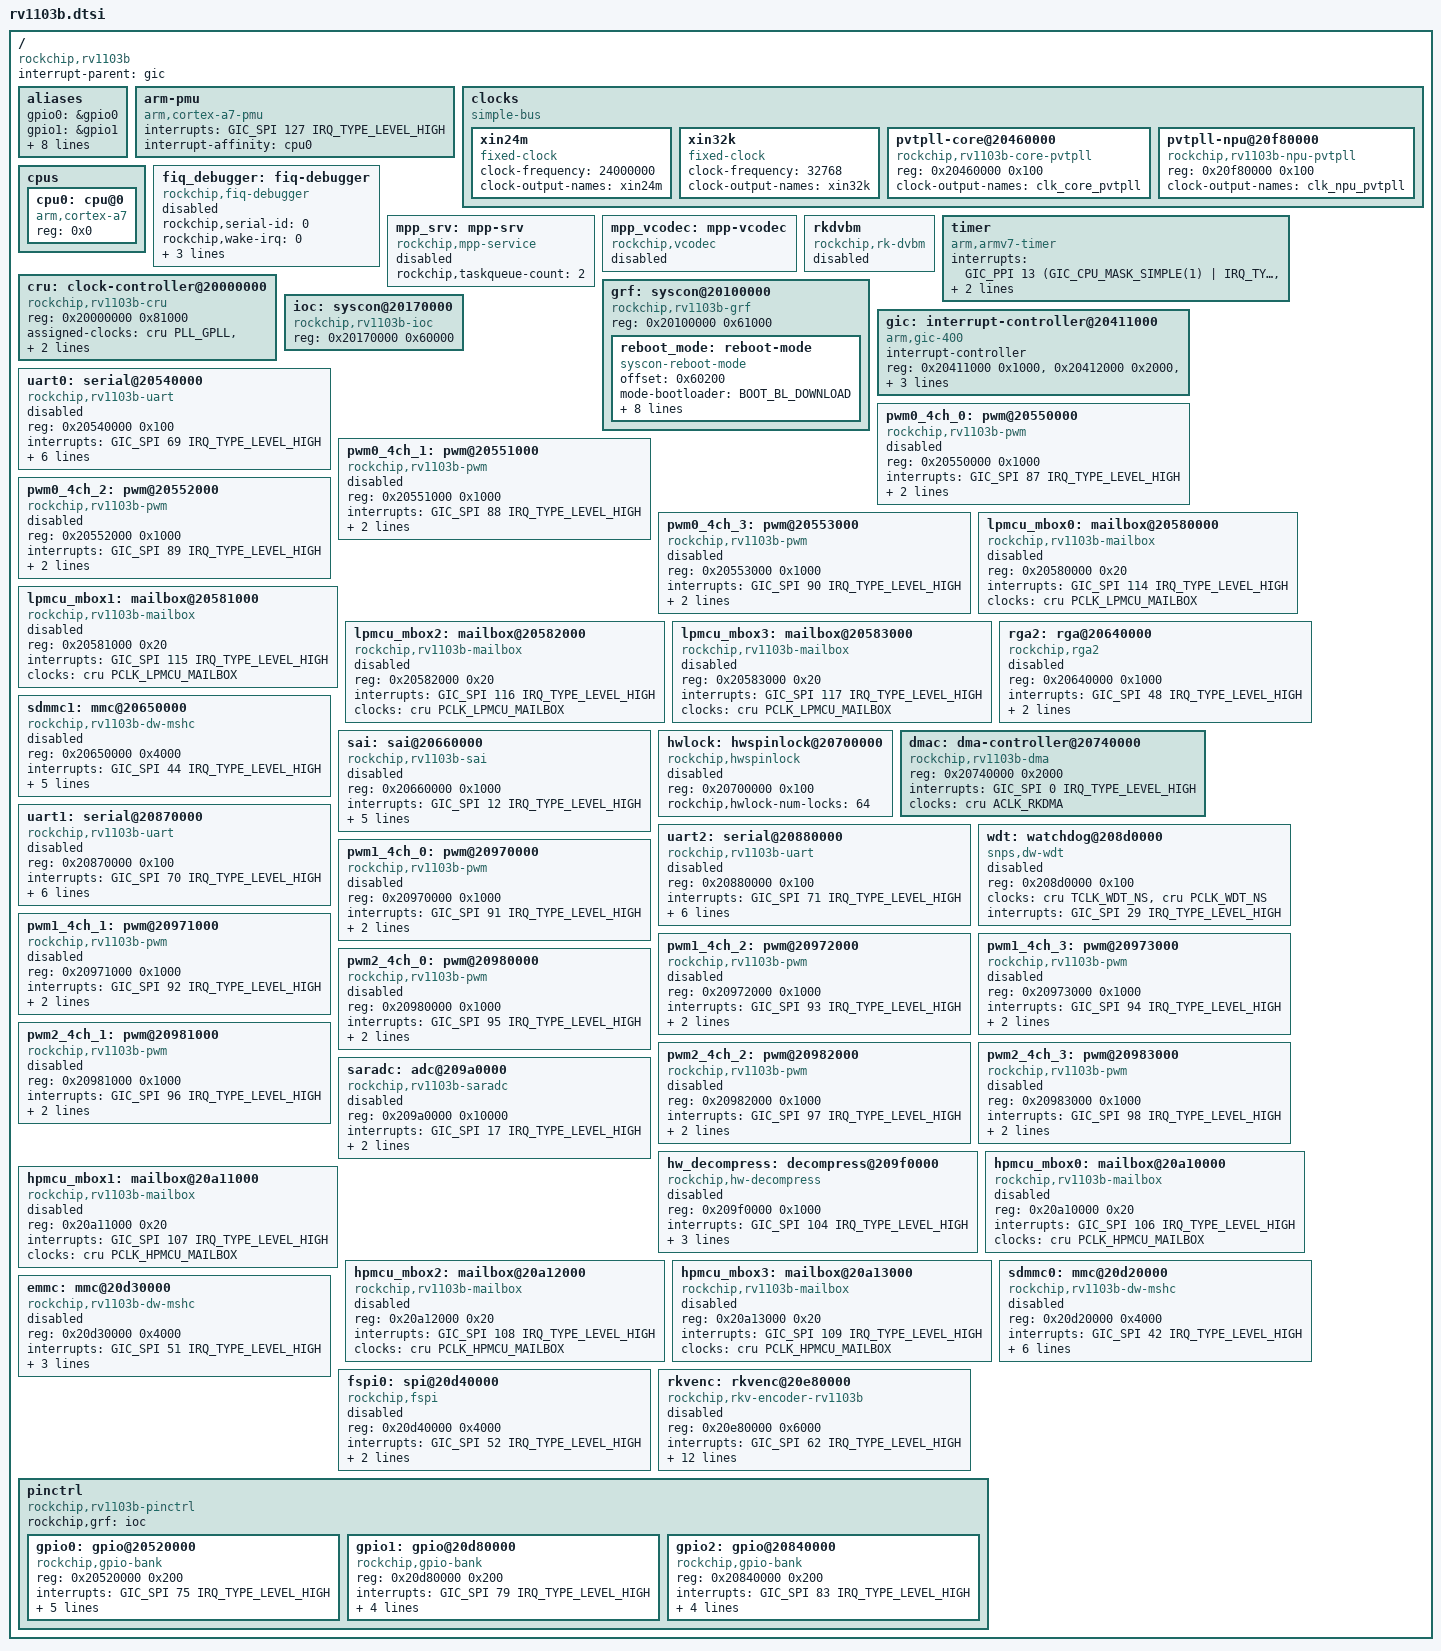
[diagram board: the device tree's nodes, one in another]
// SPDX-License-Identifier: (GPL-2.0+ OR MIT)
/*
 * Copyright (c) 2024 Rockchip Electronics Co., Ltd.
 */

#include <dt-bindings/clock/rockchip,rv1103b-cru.h>
#include <dt-bindings/gpio/gpio.h>
#include <dt-bindings/interrupt-controller/irq.h>
#include <dt-bindings/interrupt-controller/arm-gic.h>
#include <dt-bindings/pinctrl/rockchip.h>
#include <dt-bindings/soc/rockchip,boot-mode.h>
#include <dt-bindings/soc/rockchip-system-status.h>
#include <dt-bindings/thermal/thermal.h>

/ {
	#address-cells = <1>;
	#size-cells = <1>;

	compatible = "rockchip,rv1103b";

	interrupt-parent = <&gic>;

	aliases {
		gpio0 = &gpio0;
		gpio1 = &gpio1;
		gpio2 = &gpio2;
		mmc0 = &emmc;
		mmc1 = &sdmmc0;
		mmc2 = &sdmmc1;
		serial0 = &uart0;
		serial1 = &uart1;
		serial2 = &uart2;
		spi1 = &fspi0;
	};

	arm-pmu {
		compatible = "arm,cortex-a7-pmu";
		interrupts = <GIC_SPI 127 IRQ_TYPE_LEVEL_HIGH>;
		interrupt-affinity = <&cpu0>;
	};

	clocks {
		compatible = "simple-bus";
		#address-cells = <1>;
		#size-cells = <1>;
		ranges;

		xin24m: xin24m {
			compatible = "fixed-clock";
			#clock-cells = <0>;
			clock-frequency = <24000000>;
			clock-output-names = "xin24m";
		};

		xin32k: xin32k {
			compatible = "fixed-clock";
			#clock-cells = <0>;
			clock-frequency = <32768>;
			clock-output-names = "xin32k";
		};

		pvtpll-core@20460000 {
			compatible = "rockchip,rv1103b-core-pvtpll";
			reg = <0x20460000 0x100>;
			clock-output-names = "clk_core_pvtpll";
		};

		pvtpll-npu@20f80000 {
			compatible = "rockchip,rv1103b-npu-pvtpll";
			reg = <0x20f80000 0x100>;
			clock-output-names = "clk_npu_pvtpll";
		};
	};

	cpus {
		#address-cells = <1>;
		#size-cells = <0>;

		cpu0: cpu@0 {
			device_type = "cpu";
			compatible = "arm,cortex-a7";
			reg = <0x0>;
		};
	};

	fiq_debugger: fiq-debugger {
		compatible = "rockchip,fiq-debugger";
		rockchip,serial-id = <0>;
		rockchip,wake-irq = <0>;
		rockchip,irq-mode-enable = <0>;
		rockchip,baudrate = <115200>;  /* Only 115200 and 1500000 */
		interrupts = <GIC_SPI 125 IRQ_TYPE_LEVEL_HIGH>;
		status = "disabled";
	};

	mpp_srv: mpp-srv {
		compatible = "rockchip,mpp-service";
		rockchip,taskqueue-count = <2>;
		status = "disabled";
	};

	mpp_vcodec: mpp-vcodec {
		compatible = "rockchip,vcodec";
		status = "disabled";
	};

	rkdvbm: rkdvbm {
		compatible = "rockchip,rk-dvbm";
		status = "disabled";
	};

	timer {
		compatible = "arm,armv7-timer";
		interrupts = <GIC_PPI 13 (GIC_CPU_MASK_SIMPLE(1) | IRQ_TYPE_LEVEL_HIGH)>,
			     <GIC_PPI 14 (GIC_CPU_MASK_SIMPLE(1) | IRQ_TYPE_LEVEL_HIGH)>;
		clock-frequency = <24000000>;
	};

	cru: clock-controller@20000000 {
		compatible = "rockchip,rv1103b-cru";
		reg = <0x20000000 0x81000>;
		#clock-cells = <1>;
		#reset-cells = <1>;

		assigned-clocks =
			<&cru PLL_GPLL>, <&cru CLK_GPLL_DIV12>;
		assigned-clock-rates =
			<1188000000>, <100000000>;
	};

	/*
	 * Merge all GRF, each independent GRF offset is shown as bellow:
	 * VEPU_GRF:		0x20100000
	 * NPU_GRF:		0x20110000
	 * VI_GRF:		0x20120000
	 * CPU_GRF:		0x20130000
	 * DDR_GRF:		0x20140000
	 * SYS_GRF:		0x20150000
	 * PMU_GRF:		0x20160000
	 */
	grf: syscon@20100000 {
		compatible = "rockchip,rv1103b-grf", "syscon", "simple-mfd";
		reg = <0x20100000 0x61000>;

		reboot_mode: reboot-mode {
			compatible = "syscon-reboot-mode";
			offset = <0x60200>;
			mode-bootloader = <BOOT_BL_DOWNLOAD>;
			mode-charge = <BOOT_CHARGING>;
			mode-fastboot = <BOOT_FASTBOOT>;
			mode-loader = <BOOT_BL_DOWNLOAD>;
			mode-normal = <BOOT_NORMAL>;
			mode-recovery = <BOOT_RECOVERY>;
			mode-ums = <BOOT_UMS>;
			mode-panic = <BOOT_PANIC>;
			mode-watchdog = <BOOT_WATCHDOG>;
		};
	};

	ioc: syscon@20170000 {
		compatible = "rockchip,rv1103b-ioc", "syscon";
		reg = <0x20170000 0x60000>;
	};

	gic: interrupt-controller@20411000 {
		compatible = "arm,gic-400";
		interrupt-controller;
		#interrupt-cells = <3>;
		#address-cells = <0>;

		reg = <0x20411000 0x1000>,
		      <0x20412000 0x2000>,
		      <0x20414000 0x2000>,
		      <0x20416000 0x2000>;
		interrupts = <GIC_PPI 9 (GIC_CPU_MASK_SIMPLE(1) | IRQ_TYPE_LEVEL_HIGH)>;
	};

	uart0: serial@20540000 {
		compatible = "rockchip,rv1103b-uart", "snps,dw-apb-uart";
		reg = <0x20540000 0x100>;
		interrupts = <GIC_SPI 69 IRQ_TYPE_LEVEL_HIGH>;
		reg-shift = <2>;
		reg-io-width = <4>;
		dmas = <&dmac 1>, <&dmac 0>;
		clock-frequency = <24000000>;
		clocks = <&cru SCLK_UART0>, <&cru PCLK_UART0>;
		clock-names = "baudclk", "apb_pclk";
		pinctrl-names = "default";
		pinctrl-0 = <&uart0m0_xfer_pins>;
		status = "disabled";
	};

	pwm0_4ch_0: pwm@20550000 {
		compatible = "rockchip,rv1103b-pwm", "rockchip,rk3576-pwm";
		reg = <0x20550000 0x1000>;
		interrupts = <GIC_SPI 87 IRQ_TYPE_LEVEL_HIGH>;
		#pwm-cells = <3>;
		pinctrl-names = "active";
		pinctrl-0 = <&pwm0m0_ch0_pins>;
		clocks = <&cru CLK_PWM0>, <&cru PCLK_PWM0>;
		clock-names = "pwm", "pclk";
		status = "disabled";
	};

	pwm0_4ch_1: pwm@20551000 {
		compatible = "rockchip,rv1103b-pwm", "rockchip,rk3576-pwm";
		reg = <0x20551000 0x1000>;
		interrupts = <GIC_SPI 88 IRQ_TYPE_LEVEL_HIGH>;
		#pwm-cells = <3>;
		pinctrl-names = "active";
		pinctrl-0 = <&pwm0m0_ch1_pins>;
		clocks = <&cru CLK_PWM0>, <&cru PCLK_PWM0>;
		clock-names = "pwm", "pclk";
		status = "disabled";
	};

	pwm0_4ch_2: pwm@20552000 {
		compatible = "rockchip,rv1103b-pwm", "rockchip,rk3576-pwm";
		reg = <0x20552000 0x1000>;
		interrupts = <GIC_SPI 89 IRQ_TYPE_LEVEL_HIGH>;
		#pwm-cells = <3>;
		pinctrl-names = "active";
		pinctrl-0 = <&pwm0m0_ch2_pins>;
		clocks = <&cru CLK_PWM0>, <&cru PCLK_PWM0>;
		clock-names = "pwm", "pclk";
		status = "disabled";
	};

	pwm0_4ch_3: pwm@20553000 {
		compatible = "rockchip,rv1103b-pwm", "rockchip,rk3576-pwm";
		reg = <0x20553000 0x1000>;
		interrupts = <GIC_SPI 90 IRQ_TYPE_LEVEL_HIGH>;
		#pwm-cells = <3>;
		pinctrl-names = "active";
		pinctrl-0 = <&pwm0m0_ch3_pins>;
		clocks = <&cru CLK_PWM0>, <&cru PCLK_PWM0>;
		clock-names = "pwm", "pclk";
		status = "disabled";
	};

	lpmcu_mbox0: mailbox@20580000 {
		compatible = "rockchip,rv1103b-mailbox", "rockchip,rk3576-mailbox";
		reg = <0x20580000 0x20>;
		interrupts = <GIC_SPI 114 IRQ_TYPE_LEVEL_HIGH>;
		clocks = <&cru PCLK_LPMCU_MAILBOX>;
		clock-names = "pclk_mailbox";
		#mbox-cells = <1>;
		status = "disabled";
	};

	lpmcu_mbox1: mailbox@20581000 {
		compatible = "rockchip,rv1103b-mailbox", "rockchip,rk3576-mailbox";
		reg = <0x20581000 0x20>;
		interrupts = <GIC_SPI 115 IRQ_TYPE_LEVEL_HIGH>;
		clocks = <&cru PCLK_LPMCU_MAILBOX>;
		clock-names = "pclk_mailbox";
		#mbox-cells = <1>;
		status = "disabled";
	};

	lpmcu_mbox2: mailbox@20582000 {
		compatible = "rockchip,rv1103b-mailbox", "rockchip,rk3576-mailbox";
		reg = <0x20582000 0x20>;
		interrupts = <GIC_SPI 116 IRQ_TYPE_LEVEL_HIGH>;
		clocks = <&cru PCLK_LPMCU_MAILBOX>;
		clock-names = "pclk_mailbox";
		#mbox-cells = <1>;
		status = "disabled";
	};

	lpmcu_mbox3: mailbox@20583000 {
		compatible = "rockchip,rv1103b-mailbox", "rockchip,rk3576-mailbox";
		reg = <0x20583000 0x20>;
		interrupts = <GIC_SPI 117 IRQ_TYPE_LEVEL_HIGH>;
		clocks = <&cru PCLK_LPMCU_MAILBOX>;
		clock-names = "pclk_mailbox";
		#mbox-cells = <1>;
		status = "disabled";
	};

	rga2: rga@20640000 {
		compatible = "rockchip,rga2";
		reg = <0x20640000 0x1000>;
		interrupts = <GIC_SPI 48 IRQ_TYPE_LEVEL_HIGH>;
		interrupt-names = "rga2_irq";
		clocks = <&cru ACLK_RGA>, <&cru HCLK_RGA>, <&cru CLK_CORE_RGA>;
		clock-names = "aclk_rga", "hclk_rga", "clk_rga";
		status = "disabled";
	};

	sdmmc1: mmc@20650000 {
		compatible = "rockchip,rv1103b-dw-mshc", "rockchip,rk3288-dw-mshc";
		reg = <0x20650000 0x4000>;
		interrupts = <GIC_SPI 44 IRQ_TYPE_LEVEL_HIGH>;
		clocks = <&cru HCLK_SDMMC1>, <&cru CCLK_SDMMC1>;
		clock-names = "biu", "ciu";
		fifo-depth = <0x100>;
		max-frequency = <150000000>;
		pinctrl-names = "default";
		pinctrl-0 = <&sdmmc1_clk_pins &sdmmc1_cmd_pins &sdmmc1_bus4_pins>;
		status = "disabled";
	};

	sai: sai@20660000 {
		compatible = "rockchip,rv1103b-sai", "rockchip,sai-v1";
		reg = <0x20660000 0x1000>;
		interrupts = <GIC_SPI 12 IRQ_TYPE_LEVEL_HIGH>;
		clocks = <&cru MCLK_SAI>, <&cru HCLK_SAI>;
		clock-names = "mclk", "hclk";
		dmas = <&dmac 11>, <&dmac 10>;
		dma-names = "tx", "rx";
		resets = <&cru SRST_MRESETN_SAI>, <&cru SRST_HRESETN_SAI>;
		reset-names = "m", "h";
		#sound-dai-cells = <0>;
		sound-name-prefix = "SAI";
		status = "disabled";
	};

	hwlock: hwspinlock@20700000 {
		compatible = "rockchip,hwspinlock";
		reg = <0x20700000 0x100>;
		#hwlock-cells = <1>;
		rockchip,hwlock-num-locks = <64>;
		status = "disabled";
	};

	dmac: dma-controller@20740000 {
		compatible = "rockchip,rv1103b-dma", "rockchip,dma";
		reg = <0x20740000 0x2000>;
		interrupts = <GIC_SPI 0 IRQ_TYPE_LEVEL_HIGH>;
		clocks = <&cru ACLK_RKDMA>;
		clock-names = "aclk";
		#dma-cells = <1>;
	};

	uart1: serial@20870000 {
		compatible = "rockchip,rv1103b-uart", "snps,dw-apb-uart";
		reg = <0x20870000 0x100>;
		interrupts = <GIC_SPI 70 IRQ_TYPE_LEVEL_HIGH>;
		reg-shift = <2>;
		reg-io-width = <4>;
		dmas = <&dmac 3>, <&dmac 2>;
		clock-frequency = <24000000>;
		clocks = <&cru SCLK_UART1>, <&cru PCLK_UART1>;
		clock-names = "baudclk", "apb_pclk";
		pinctrl-names = "default";
		pinctrl-0 = <&uart1m0_xfer_pins>;
		status = "disabled";
	};

	uart2: serial@20880000 {
		compatible = "rockchip,rv1103b-uart", "snps,dw-apb-uart";
		reg = <0x20880000 0x100>;
		interrupts = <GIC_SPI 71 IRQ_TYPE_LEVEL_HIGH>;
		reg-shift = <2>;
		reg-io-width = <4>;
		dmas = <&dmac 5>, <&dmac 4>;
		clock-frequency = <24000000>;
		clocks = <&cru SCLK_UART2>, <&cru PCLK_UART2>;
		clock-names = "baudclk", "apb_pclk";
		pinctrl-names = "default";
		pinctrl-0 = <&uart2m0_xfer_pins>;
		status = "disabled";
	};

	wdt: watchdog@208d0000 {
		compatible = "snps,dw-wdt";
		reg = <0x208d0000 0x100>;
		clocks = <&cru TCLK_WDT_NS>, <&cru PCLK_WDT_NS>;
		clock-names = "tclk", "pclk";
		interrupts = <GIC_SPI 29 IRQ_TYPE_LEVEL_HIGH>;
		status = "disabled";
	};

	pwm1_4ch_0: pwm@20970000 {
		compatible = "rockchip,rv1103b-pwm", "rockchip,rk3576-pwm";
		reg = <0x20970000 0x1000>;
		interrupts = <GIC_SPI 91 IRQ_TYPE_LEVEL_HIGH>;
		#pwm-cells = <3>;
		pinctrl-names = "active";
		pinctrl-0 = <&pwm1m0_ch0_pins>;
		clocks = <&cru CLK_PWM1>, <&cru PCLK_PWM1>;
		clock-names = "pwm", "pclk";
		status = "disabled";
	};

	pwm1_4ch_1: pwm@20971000 {
		compatible = "rockchip,rv1103b-pwm", "rockchip,rk3576-pwm";
		reg = <0x20971000 0x1000>;
		interrupts = <GIC_SPI 92 IRQ_TYPE_LEVEL_HIGH>;
		#pwm-cells = <3>;
		pinctrl-names = "active";
		pinctrl-0 = <&pwm1m0_ch1_pins>;
		clocks = <&cru CLK_PWM1>, <&cru PCLK_PWM1>;
		clock-names = "pwm", "pclk";
		status = "disabled";
	};

	pwm1_4ch_2: pwm@20972000 {
		compatible = "rockchip,rv1103b-pwm", "rockchip,rk3576-pwm";
		reg = <0x20972000 0x1000>;
		interrupts = <GIC_SPI 93 IRQ_TYPE_LEVEL_HIGH>;
		#pwm-cells = <3>;
		pinctrl-names = "active";
		pinctrl-0 = <&pwm1m0_ch2_pins>;
		clocks = <&cru CLK_PWM1>, <&cru PCLK_PWM1>;
		clock-names = "pwm", "pclk";
		status = "disabled";
	};

	pwm1_4ch_3: pwm@20973000 {
		compatible = "rockchip,rv1103b-pwm", "rockchip,rk3576-pwm";
		reg = <0x20973000 0x1000>;
		interrupts = <GIC_SPI 94 IRQ_TYPE_LEVEL_HIGH>;
		#pwm-cells = <3>;
		pinctrl-names = "active";
		pinctrl-0 = <&pwm1m0_ch3_pins>;
		clocks = <&cru CLK_PWM1>, <&cru PCLK_PWM1>;
		clock-names = "pwm", "pclk";
		status = "disabled";
	};

	pwm2_4ch_0: pwm@20980000 {
		compatible = "rockchip,rv1103b-pwm", "rockchip,rk3576-pwm";
		reg = <0x20980000 0x1000>;
		interrupts = <GIC_SPI 95 IRQ_TYPE_LEVEL_HIGH>;
		#pwm-cells = <3>;
		pinctrl-names = "active";
		pinctrl-0 = <&pwm2m0_ch0_pins>;
		clocks = <&cru CLK_PWM2>, <&cru PCLK_PWM2>;
		clock-names = "pwm", "pclk";
		status = "disabled";
	};

	pwm2_4ch_1: pwm@20981000 {
		compatible = "rockchip,rv1103b-pwm", "rockchip,rk3576-pwm";
		reg = <0x20981000 0x1000>;
		interrupts = <GIC_SPI 96 IRQ_TYPE_LEVEL_HIGH>;
		#pwm-cells = <3>;
		pinctrl-names = "active";
		pinctrl-0 = <&pwm2m0_ch1_pins>;
		clocks = <&cru CLK_PWM2>, <&cru PCLK_PWM2>;
		clock-names = "pwm", "pclk";
		status = "disabled";
	};

	pwm2_4ch_2: pwm@20982000 {
		compatible = "rockchip,rv1103b-pwm", "rockchip,rk3576-pwm";
		reg = <0x20982000 0x1000>;
		interrupts = <GIC_SPI 97 IRQ_TYPE_LEVEL_HIGH>;
		#pwm-cells = <3>;
		pinctrl-names = "active";
		pinctrl-0 = <&pwm2m0_ch2_pins>;
		clocks = <&cru CLK_PWM2>, <&cru PCLK_PWM2>;
		clock-names = "pwm", "pclk";
		status = "disabled";
	};

	pwm2_4ch_3: pwm@20983000 {
		compatible = "rockchip,rv1103b-pwm", "rockchip,rk3576-pwm";
		reg = <0x20983000 0x1000>;
		interrupts = <GIC_SPI 98 IRQ_TYPE_LEVEL_HIGH>;
		#pwm-cells = <3>;
		pinctrl-names = "active";
		pinctrl-0 = <&pwm2m0_ch3_pins>;
		clocks = <&cru CLK_PWM2>, <&cru PCLK_PWM2>;
		clock-names = "pwm", "pclk";
		status = "disabled";
	};

	saradc: adc@209a0000 {
		compatible = "rockchip,rv1103b-saradc", "rockchip,rk3588-saradc";
		reg = <0x209a0000 0x10000>;
		interrupts = <GIC_SPI 17 IRQ_TYPE_LEVEL_HIGH>;
		#io-channel-cells = <1>;
		clocks = <&cru CLK_SARADC>, <&cru PCLK_SARADC>;
		clock-names = "saradc", "apb_pclk";
		resets = <&cru SRST_PRESETN_SARADC>;
		reset-names = "saradc-apb";
		status = "disabled";
	};

	hw_decompress: decompress@209f0000 {
		compatible = "rockchip,hw-decompress";
		reg = <0x209f0000 0x1000>;
		interrupts = <GIC_SPI 104 IRQ_TYPE_LEVEL_HIGH>;
		clocks = <&cru ACLK_DECOM>, <&cru DCLK_DECOM>, <&cru PCLK_DECOM>;
		clock-names = "aclk", "dclk", "pclk";
		resets = <&cru SRST_DRESETN_DECOM>;
		reset-names = "dresetn";
		status = "disabled";
	};

	hpmcu_mbox0: mailbox@20a10000 {
		compatible = "rockchip,rv1103b-mailbox", "rockchip,rk3576-mailbox";
		reg = <0x20a10000 0x20>;
		interrupts = <GIC_SPI 106 IRQ_TYPE_LEVEL_HIGH>;
		clocks = <&cru PCLK_HPMCU_MAILBOX>;
		clock-names = "pclk_mailbox";
		#mbox-cells = <1>;
		status = "disabled";
	};

	hpmcu_mbox1: mailbox@20a11000 {
		compatible = "rockchip,rv1103b-mailbox", "rockchip,rk3576-mailbox";
		reg = <0x20a11000 0x20>;
		interrupts = <GIC_SPI 107 IRQ_TYPE_LEVEL_HIGH>;
		clocks = <&cru PCLK_HPMCU_MAILBOX>;
		clock-names = "pclk_mailbox";
		#mbox-cells = <1>;
		status = "disabled";
	};

	hpmcu_mbox2: mailbox@20a12000 {
		compatible = "rockchip,rv1103b-mailbox", "rockchip,rk3576-mailbox";
		reg = <0x20a12000 0x20>;
		interrupts = <GIC_SPI 108 IRQ_TYPE_LEVEL_HIGH>;
		clocks = <&cru PCLK_HPMCU_MAILBOX>;
		clock-names = "pclk_mailbox";
		#mbox-cells = <1>;
		status = "disabled";
	};

	hpmcu_mbox3: mailbox@20a13000 {
		compatible = "rockchip,rv1103b-mailbox", "rockchip,rk3576-mailbox";
		reg = <0x20a13000 0x20>;
		interrupts = <GIC_SPI 109 IRQ_TYPE_LEVEL_HIGH>;
		clocks = <&cru PCLK_HPMCU_MAILBOX>;
		clock-names = "pclk_mailbox";
		#mbox-cells = <1>;
		status = "disabled";
	};

	sdmmc0: mmc@20d20000 {
		compatible = "rockchip,rv1103b-dw-mshc", "rockchip,rk3288-dw-mshc";
		reg = <0x20d20000 0x4000>;
		interrupts = <GIC_SPI 42 IRQ_TYPE_LEVEL_HIGH>;
		clocks = <&cru HCLK_SDMMC0>, <&cru CCLK_SDMMC0>;
		clock-names = "biu", "ciu";
		fifo-depth = <0x100>;
		max-frequency = <150000000>;
		pinctrl-names = "normal", "idle";
		pinctrl-0 = <&sdmmc0_clk_pins &sdmmc0_cmd_pins &sdmmc0_det_pins &sdmmc0_bus4_pins>;
		pinctrl-1 = <&sdmmc0_idle_pins &sdmmc0_det_pins>;
		status = "disabled";
	};

	emmc: mmc@20d30000 {
		compatible = "rockchip,rv1103b-dw-mshc", "rockchip,rk3288-dw-mshc";
		reg = <0x20d30000 0x4000>;
		interrupts = <GIC_SPI 51 IRQ_TYPE_LEVEL_HIGH>;
		clocks = <&cru HCLK_EMMC>, <&cru CCLK_EMMC>;
		clock-names = "biu", "ciu";
		fifo-depth = <0x100>;
		max-frequency = <150000000>;
		status = "disabled";
	};

	fspi0: spi@20d40000 {
		compatible = "rockchip,fspi";
		reg = <0x20d40000 0x4000>;
		interrupts = <GIC_SPI 52 IRQ_TYPE_LEVEL_HIGH>;
		clocks = <&cru SCLK_SFC_2X>, <&cru HCLK_SFC>;
		clock-names = "clk_sfc", "hclk_sfc";
		rockchip,sclk-x2-bypass;
		#address-cells = <1>;
		#size-cells = <0>;
		status = "disabled";
	};

	rkvenc: rkvenc@20e80000 {
		compatible = "rockchip,rkv-encoder-rv1103b";
		reg = <0x20e80000 0x6000>;
		interrupts = <GIC_SPI 62 IRQ_TYPE_LEVEL_HIGH>;
		interrupt-names = "irq_rkvenc";
		clocks = <&cru ACLK_VEPU>, <&cru HCLK_VEPU>, <&cru CLK_CORE_VEPU>;
		clock-names = "aclk_vcodec", "hclk_vcodec", "clk_core";
		rockchip,normal-rates = <400000000>, <0>, <400000000>;
		assigned-clocks = <&cru ACLK_VEPU>, <&cru CLK_CORE_VEPU>;
		assigned-clock-rates = <400000000>, <400000000>;
		resets = <&cru SRST_ARESETN_VEPU>, <&cru SRST_HRESETN_VEPU>,
			 <&cru SRST_RESETN_CORE_VEPU>;
		reset-names = "video_a", "video_h", "video_core";
		rockchip,srv = <&mpp_srv>;
		rockchip,taskqueue-node = <0>;
		dvbm = <&rkdvbm>;
		status = "disabled";
	};

	pinctrl: pinctrl {
		compatible = "rockchip,rv1103b-pinctrl";
		rockchip,grf = <&ioc>;
		#address-cells = <1>;
		#size-cells = <1>;
		ranges;

		gpio0: gpio@20520000 {
			compatible = "rockchip,gpio-bank";
			reg = <0x20520000 0x200>;
			interrupts = <GIC_SPI 75 IRQ_TYPE_LEVEL_HIGH>;
			clocks = <&cru PCLK_PMU_GPIO0>, <&cru DBCLK_PMU_GPIO0>;
			gpio-controller;
			#gpio-cells = <2>;
			gpio-ranges = <&pinctrl 0 0 32>;
			interrupt-controller;
			#interrupt-cells = <2>;
		};

		gpio1: gpio@20d80000 {
			compatible = "rockchip,gpio-bank";
			reg = <0x20d80000 0x200>;
			interrupts = <GIC_SPI 79 IRQ_TYPE_LEVEL_HIGH>;
			clocks = <&cru PCLK_GPIO1>, <&cru DBCLK_GPIO1>;
			gpio-controller;
			#gpio-cells = <2>;
			gpio-ranges = <&pinctrl 0 32 32>;
			interrupt-controller;
			#interrupt-cells = <2>;
		};

		gpio2: gpio@20840000 {
			compatible = "rockchip,gpio-bank";
			reg = <0x20840000 0x200>;
			interrupts = <GIC_SPI 83 IRQ_TYPE_LEVEL_HIGH>;
			clocks = <&cru PCLK_GPIO2>, <&cru DBCLK_GPIO2>;
			gpio-controller;
			#gpio-cells = <2>;
			gpio-ranges = <&pinctrl 0 64 32>;
			interrupt-controller;
			#interrupt-cells = <2>;
		};
	};
};

#include "rv1103b-pinctrl.dtsi"
